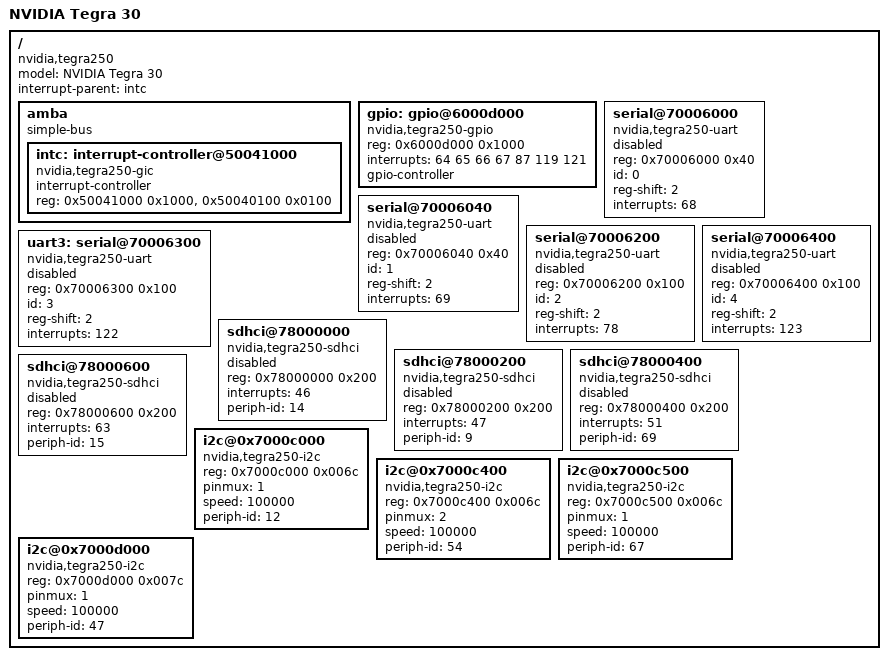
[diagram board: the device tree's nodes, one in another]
/include/ "skeleton.dtsi"

/ {
	model = "NVIDIA Tegra 30";
	compatible = "nvidia,tegra250";
	interrupt-parent = <&intc>;

	amba {
		compatible = "simple-bus";
		#address-cells = <1>;
		#size-cells = <1>;
		ranges;

		intc: interrupt-controller@50041000 {
			compatible = "nvidia,tegra250-gic", "arm,gic";
			interrupt-controller;
			#interrupt-cells = <1>;
			reg = < 0x50041000 0x1000 >,
			      < 0x50040100 0x0100 >;
		};
	};

	gpio: gpio@6000d000 {
		compatible = "nvidia,tegra250-gpio", "ns16550";
		reg = < 0x6000d000 0x1000 >;
		interrupts = < 64 65 66 67 87 119 121 >;
		#gpio-cells = <2>;
		gpio-controller;
	};

	serial@70006000 {
		compatible = "nvidia,tegra250-uart", "ns16550";
		reg = <0x70006000 0x40>;
		id = <0>;
		reg-shift = <2>;
		interrupts = < 68 >;
		status = "disabled";
	};

	serial@70006040 {
		compatible = "nvidia,tegra250-uart", "ns16550";
		reg = <0x70006040 0x40>;
		id = <1>;
		reg-shift = <2>;
		interrupts = < 69 >;
		status = "disabled";
	};

	serial@70006200 {
		compatible = "nvidia,tegra250-uart", "ns16550";
		reg = <0x70006200 0x100>;
		id = <2>;
		reg-shift = <2>;
		interrupts = < 78 >;
		status = "disabled";
	};

	uart3: serial@70006300 {
		compatible = "nvidia,tegra250-uart", "ns16550";
		reg = <0x70006300 0x100>;
		id = <3>;
		reg-shift = <2>;
		interrupts = < 122 >;
		status = "disabled";
	};

	serial@70006400 {
		compatible = "nvidia,tegra250-uart", "ns16550";
		reg = <0x70006400 0x100>;
		id = <4>;
		reg-shift = <2>;
		interrupts = < 123 >;
		status = "disabled";
	};

	sdhci@78000000 {
		compatible = "nvidia,tegra250-sdhci";
		reg = <0x78000000 0x200>;
		interrupts = <46>;
                periph-id = <14>;	// PERIPH_ID_SDMMC1
		status = "disabled";
	};

	sdhci@78000200 {
		compatible = "nvidia,tegra250-sdhci";
		reg = <0x78000200 0x200>;
		interrupts = <47>;
                periph-id = <9>;	// PERIPH_ID_SDMMC2
		status = "disabled";
	};

	sdhci@78000400 {
		compatible = "nvidia,tegra250-sdhci";
		reg = <0x78000400 0x200>;
		interrupts = <51>;
                periph-id = <69>;	// PERIPH_ID_SDMMC3
		status = "disabled";
	};

	sdhci@78000600 {
		compatible = "nvidia,tegra250-sdhci";
		reg = <0x78000600 0x200>;
		interrupts = <63>;
                periph-id = <15>;	// PERIPH_ID_SDMMC4
		status = "disabled";
	};

	i2c@0x7000c000 {
		compatible = "nvidia,tegra250-i2c";
		reg = <0x7000c000 0x006c>;
		pinmux = <1>;
		speed = <100000>;
		periph-id = <12>;	// PERIPH_ID_I2C1
	};

	i2c@0x7000c400 {
		compatible = "nvidia,tegra250-i2c";
		reg = <0x7000c400 0x006c>;
		pinmux = <2>;
		speed = <100000>;
		periph-id = <54>;	// PERIPH_ID_I2C2
	};

	i2c@0x7000c500 {
		compatible = "nvidia,tegra250-i2c";
		reg = <0x7000c500 0x006c>;
		pinmux = <1>;
		speed = <100000>;
		periph-id = <67>;	// PERIPH_ID_I2C3
	};

	i2c@0x7000d000 {
		compatible = "nvidia,tegra250-i2c";
		reg = <0x7000d000 0x007c>;
		pinmux = <1>;
		speed = <100000>;
		periph-id = <47>;	// PERIPH_ID_DVC_I2C
	};
};

